# dma_reva_me10 register map
Registers are 32-bit, read-write, no defined reset value unless marked. A register's access mark holds for its fields unless they carry their own. Offsets are from the block's base; lines under a group give offsets from that group; [hi:lo] are bit positions; {n}, {i} and the like mark numbered series; 'fields as' and 'values as' point back to an identical list; <NAME> marks a mode.

## Memory map
0x40028000 DMA size 0x1000 — DMA Controller Fully programmable, chaining capable DMA channels.

## Interrupts
28 DMA0 (DMA)
29 DMA1 (DMA)
30 DMA2 (DMA)
31 DMA3 (DMA)
{n+64} DMA{n} (DMA) (n=4..15)

## DMA — DMA Controller Fully programmable, chaining capable DMA channels.
Base 0x40028000
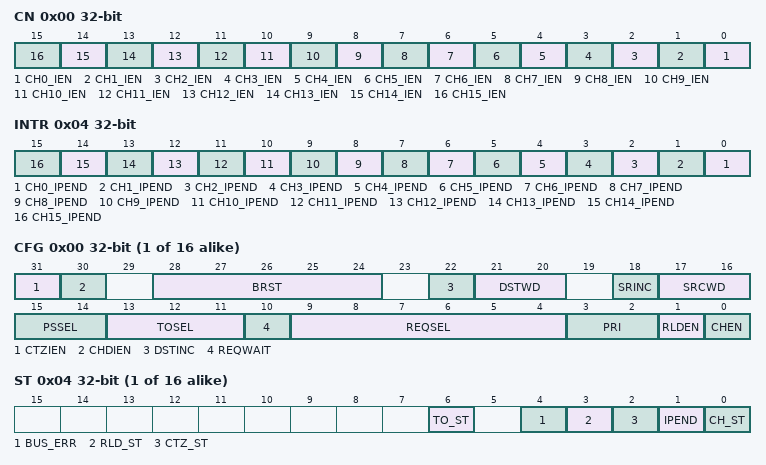
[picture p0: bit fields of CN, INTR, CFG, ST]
0x00 CN access not given — DMA Control Register.
  [all] fields
    0=dis (Disable.); 1=en (Enable.)
  [n] CH{n}_IEN (n=0..15) — Channel {n} Interrupt Enable.
0x04 INTR ro — DMA Interrupt Register.
  [all] fields
    0=inactive (Channel interrupt not currently asserted.); 1=pending (Channel interrupt pending.)
  [n] CH{n}_IPEND (n=0..15) — Channel {n} Interrupt Pending.
{0x100+0x20*i} CH[{i}] (i=0..15) group — DMA Channel registers.
  0x00 CFG — DMA Channel Configuration Register.
    [31] CTZIEN — Count-to-zero Interrupts Enable. When enabled, the IPEND will be set to 1 whenever a count-to-zero event occurs.
      0=dis (Disable.); 1=en (Enable.)
    [30] CHDIEN — Channel Disable Interrupt Enable. When enabled, the IPEND will be set to 1 whenever CH_ST changes from 1 to 0.
      0=dis (Disable.); 1=en (Enable.)
    [28:24] BRST — Burst Size. The number of bytes to be transferred into and out of the DMA FIFO in a single burst. Burst size equals 1 + value stored in this field.
    [22] DSTINC — Destination Increment Enable. This bit enables DMA_DST increment upon every AHB transaction. This bit is forced to 0 for DMA transmit to peripherals.
      0=dis (Disable.); 1=en (Enable.)
    [21:20] DSTWD — Destination Width. Indicates the width of the each AHB transactions to the destination peripheral or memory. (The actual width may be less than this if there are insufficient bytes in the DMA FIFO for the full width).
      0=byte; 1=halfWord; 2=word
    [18] SRINC — Source Increment Enable. This bit enables DMA_SRC increment upon every AHB transaction. This bit is forced to 0 for DMA receive from peripherals.
      0=dis (Disable.); 1=en (Enable.)
    [17:16] SRCWD — Source Width. In most cases, this will be the data width of each AHB transactions. However, the width will be reduced in the cases where DMA_CNT indicates a smaller value.
      0=byte; 1=halfWord; 2=word
    [15:14] PSSEL — Pre-Scale Select. Selects the Pre-Scale divider for timer clock input.
      0=dis (Disable timer.); 1=div256 (hclk / 256.); 2=div64k (hclk / 64k.); 3=div16M (hclk / 16M.)
    [13:11] TOSEL — Time-Out Select. Selects the number of prescale clocks seen by the channel timer before a time-out conditions is generated for this channel. Important note: since the prescaler runs independent of the individual channel timers, the actual number of Pre-Scale clock edges seen has a margin of error equal to a single Pre-Scale clock.
      0=to4 (Timeout of 3 to 4 prescale clocks.); 1=to8 (Timeout of 7 to 8 prescale clocks.); 2=to16 (Timeout of 15 to 16 prescale clocks.); 3=to32 (Timeout of 31 to 32 prescale clocks.); 4=to64 (Timeout of 63 to 64 prescale clocks.); 5=to128 (Timeout of 127 to 128 prescale clocks.); 6=to256 (Timeout of 255 to 256 prescale clocks.); 7=to512 (Timeout of 511 to 512 prescale clocks.)
    [10] REQWAIT — Request Wait Enable. When enabled, delay timer start until DMA request transitions from active to inactive.
      0=Normal timer start; 1=Delay timer start
    [9:4] REQSEL — Request Select. Select DMA request line for this channel. If memory-to-memory is selected, the channel operates as if the request is always active.
      0=MEMTOMEM (Memory To Memory); 1=SPI0RX; 2=SPI1RX; 3=SPI2RX; 4=UART0RX; 5=UART1RX; 7=I2C0RX; 8=I2C1RX; 9=ADC (Analog-to-Digital Converter Channel); 14=UART2RX; 15=SPI3RX; 16=SPIMSSRX; {v}=USBRXEP{v-16} (USB Endpoint {v-16} RX) (v=17..27); 33=SPI0TX; 34=SPI1TX; 35=SPI2TX; 36=UART0TX; 37=UART1TX; 39=I2C0TX; 40=I2C1TX; 46=UART2TX; 47=SPI3TX; 48=SPIMSSTX; {v}=USBTXEP{v-48} (USB Endpoint {v-48} TX) (v=49..59)
    [3:2] PRI — DMA Priority.
      0=Highest Priority; 1=medHigh (Medium High Priority.); 2=medLow (Medium Low Priority.); 3=low (Lowest Priority.)
    [1] RLDEN — Reload Enable. Setting this bit to 1 enables DMA_SRC, DMA_DST and DMA_CNT to be reloaded with their corresponding reload registers upon count-to-zero. This bit is also writeable in the Count Reload Register. Refer to the description on Buffer Chaining for use of this bit. If buffer chaining is not used this bit must be written with a 0. This bit should be set after the reload registers have been programmed.
      0=dis (Disable.); 1=en (Enable.)
    [0] CHEN — Channel Enable. This bit is automatically cleared when DMA_ST.CH_ST changes from 1 to 0.
      0=dis (Disable.); 1=en (Enable.)
  0x04 ST — DMA Channel Status Register.
    [6] TO_ST write-1-clears — Time-Out Status.
      on read: 0=noEvent (The event has not occurred.); 1=expired (The event has occurred.) | on write: 1=Clears the interrupt flag
    [4] BUS_ERR write-1-clears — Bus Error. Indicates that an AHB abort was received and the channel has been disabled.
      on read: 0=noEvent (The event has not occurred.); 1=bus_err (The event has occurred.) | on write: 1=Clears the interrupt flag
    [3] RLD_ST write-1-clears — Reload Status.
      on read: 0=noEvent (The event has not occurred.); 1=reloaded (The event has occurred.) | on write: 1=Clears the interrupt flag
    [2] CTZ_ST write-1-clears — Count-to-Zero (CTZ) Status
      on read: 0=noEvent (The event has not occurred.); 1=ctz_occur (The event has occurred.) | on write: 1=Clears the interrupt flag
    [1] IPEND ro — Channel Interrupt.
      0=inactive (No interrupt is pending.); 1=pending (An interrupt is pending.)
    [0] CH_ST ro — Channel Status. This bit is used to indicate to the programmer when it is safe to change the configuration, address, and count registers for the channel. Whenever this bit is cleared by hardware, the DMA_CFG.CHEN bit is also cleared (if not cleared already).
      0=disabled; 1=enabled
  0x08 SRC — Source Device Address. If SRCINC=1, the counter bits are incremented by 1,2, or 4, depending on the data width of each AHB cycle. For peripheral transfers, some or all of the actual address bits are fixed. If SRCINC=0, this register remains constant. In the case where a count-to-zero condition occurs while RLDEN=1, the register is reloaded with the contents of DMA_SRC_RLD.
    [31:0] ADDR
  0x0C DST — Destination Device Address. For peripheral transfers, some or all of the actual address bits are fixed. If DSTINC=1, this register is incremented on every AHB write out of the DMA FIFO. They are incremented by 1, 2, or 4, depending on the data width of each AHB cycle. In the case where a count-to-zero condition occurs while RLDEN=1, the register is reloaded with DMA_DST_RLD.
    [31:0] ADDR
  0x10 CNT — DMA Counter. The user loads this register with the number of bytes to transfer. This counter decreases on every AHB cycle into the DMA FIFO. The decrement will be 1, 2, or 4 depending on the data width of each AHB cycle. When the counter reaches 0, a count-to-zero condition is triggered.
    [23:0] CNT — DMA Counter.
  0x14 SRC_RLD — Source Address Reload Value. The value of this register is loaded into DMA0_SRC upon a count-to-zero condition.
    [30:0] SRC_RLD — Source Address Reload Value.
  0x18 DST_RLD — Destination Address Reload Value. The value of this register is loaded into DMA0_DST upon a count-to-zero condition.
    [30:0] DST_RLD — Destination Address Reload Value.
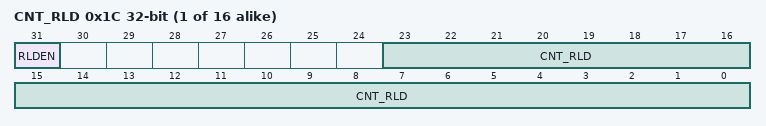
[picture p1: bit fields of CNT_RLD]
  0x1C CNT_RLD — DMA Channel Count Reload Register.
    [31] RLDEN — Reload Enable. This bit should be set after the address reload registers have been programmed. This bit is automatically cleared to 0 when reload occurs.
      0=dis (Disable.); 1=en (Enable.)
    [23:0] CNT_RLD — Count Reload Value. The value of this register is loaded into DMA0_CNT upon a count-to-zero condition.
